# CM41x_M0 register map
Vendor: Analog Devices; Series: CM41x_M0; File version: 1p0
CPU: CM0 r0p0, little endian, MPU, FPU, 4 interrupt priority bits
Registers are 32-bit, read-write, reset 0x0 unless marked. A register's access mark holds for its fields unless they carry their own. Offsets are from the block's base; [hi:lo] are bit positions; {n}, {i} and the like mark numbered series.

## SYSBLK0 — Pads Controller
Base 0x41000000
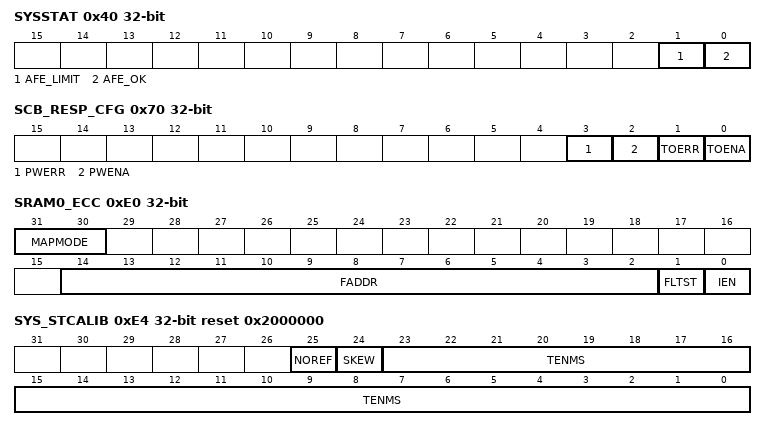
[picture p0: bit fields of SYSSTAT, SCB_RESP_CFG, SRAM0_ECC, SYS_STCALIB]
0x40 SYSSTAT — System Status Register
  [1] AFE_LIMIT ro — Status of AFE_LIMIT signal
  [0] AFE_OK ro — Status of AFE_OK Signal
0x70 SCB_RESP_CFG — SCB Response Configuration Register
  [3] PWERR — Posted Write Error
  [2] PWENA — Posted Write Error Interrupt Enable
  [1] TOERR — Timeout Error
  [0] TOENA — Enable SCB Timeout Interrupt
0x74 SCB_TIMEOUT_VALUE
  [15:0] DATA range 0x00000000..0x0000FFFF — Timeout Value
0x80 ENG_MODE_CFG0 — Engineering Mode Configuration Register 0
  [17] LBA_COMB_MODE range 0x00000000..0x00000001 — LBA Combinatorial mode
0xB4 M0_VTOR reset 0x200F0000 — Vector Table Base Offset Register
  [31:8] TBLOFF range 0x00000000..0x00FFFFFF — Vector Table Base Offset
0xE0 SRAM0_ECC — M0 SRAM ECC Register
  [31:30] MAPMODE range 0x00000000..0x00000003 — ECC Bypass Modes
  [14:2] FADDR ro — ECC Fault Address
  [1] FLTST range 0x00000000..0x00000001 — Fault Status
  [0] IEN range 0x00000000..0x00000001 — Interrupt Enable
0xE4 SYS_STCALIB reset 0x2000000 — System Register
  [25] NOREF ro — No External Reference
  [24] SKEW range 0x00000000..0x00000001 — SCLK exact multiple of 10ms
  [23:0] TENMS range 0x00000000..0x00FFFFFF — Tick Calibration 10s Microseconds
0xE8 IRQ_LATENCY reset 0xD — M0 IRQ Latency Register
  [7:0] VALUE range 0x00000000..0x000000FF — IRQ LATENCY VALUE
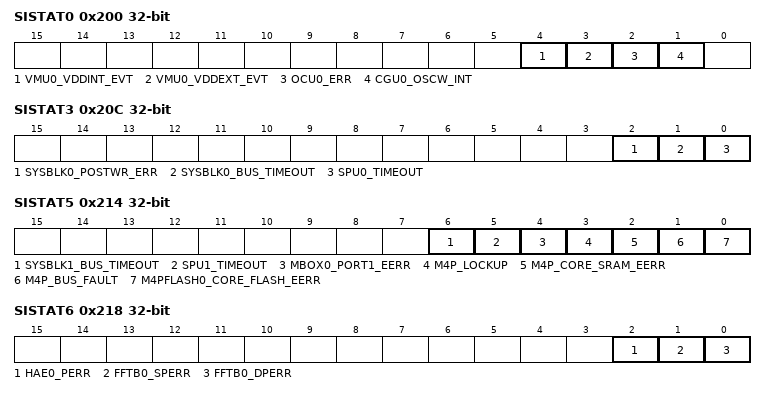
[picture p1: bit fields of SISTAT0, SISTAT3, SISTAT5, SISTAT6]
0x200 SISTAT0 — Shared Interrupt 0 Status Register
  [4] VMU0_VDDINT_EVT range 0x00000000..0x00000001 — Shared INTR_0 status bit (From VMU[0]_VDDINT_EVT)
  [3] VMU0_VDDEXT_EVT range 0x00000000..0x00000001 — Shared INTR_0 status bit (From VMU[0]_VDDEXT_EVT)
  [2] OCU0_ERR range 0x00000000..0x00000001 — Shared INTR_0 status bit (From OCU[0]_ERR)
  [1] CGU0_OSCW_INT range 0x00000000..0x00000001 — Shared INTR_0 status bit (From CGU[0]_OSCW_INT)
0x20C SISTAT3 — Shared Interrupt 3 Status Register
  [2] SYSBLK0_POSTWR_ERR range 0x00000000..0x00000001 — Shared INTR_3 status bit (From SYSBLK[0]_POSTWR_ERR)
  [1] SYSBLK0_BUS_TIMEOUT range 0x00000000..0x00000001 — Shared INTR_3 status bit (From SYSBLK[0]_BUS_TIMEOUT)
  [0] SPU0_TIMEOUT range 0x00000000..0x00000001 — Shared INTR_3 status bit (From SPU[0]_TIMEOUT)
0x214 SISTAT5 — Shared Interrupt 5 Status Register
  [6] SYSBLK1_BUS_TIMEOUT range 0x00000000..0x00000001 — Shared INTR_5 status bit (From SYSBLK[1]_BUS_TIMEOUT)
  [5] SPU1_TIMEOUT range 0x00000000..0x00000001 — Shared INTR_5 status bit (From SPU[1]_TIMEOUT)
  [4] MBOX0_PORT1_EERR range 0x00000000..0x00000001 — Shared INTR_5 status bit (From MBOX[0]_PORT1_EERR)
  [3] M4P_LOCKUP range 0x00000000..0x00000001 — Shared INTR_5 status bit (From M4P_LOCKUP)
  [2] M4P_CORE_SRAM_EERR range 0x00000000..0x00000001 — Shared INTR_5 status bit (From M4P_CORE_SRAM_EERR)
  [1] M4P_BUS_FAULT range 0x00000000..0x00000001 — Shared INTR_5 status bit (From M4P_BUS_FAULT)
  [0] M4PFLASH0_CORE_FLASH_EERR range 0x00000000..0x00000001 — Shared INTR_5 status bit (From M4PFLASH[0]_CORE_FLASH_EERR)
0x218 SISTAT6 — Shared Interrupt 6 Status Register
  [2] HAE0_PERR range 0x00000000..0x00000001 — Shared INTR_6 status bit (From HAE[0]_PERR)
  [1] FFTB0_SPERR range 0x00000000..0x00000001 — Shared INTR_6 status bit (From FFTB[0]_SPERR)
  [0] FFTB0_DPERR range 0x00000000..0x00000001 — Shared INTR_6 status bit (From FFTB[0]_DPERR)
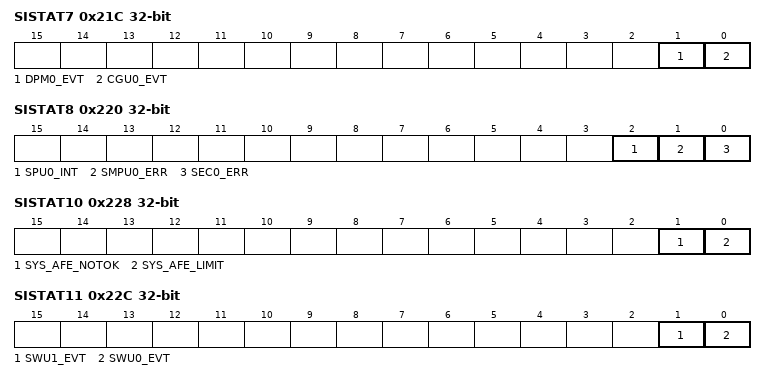
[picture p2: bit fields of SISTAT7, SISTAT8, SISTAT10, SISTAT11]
0x21C SISTAT7 — Shared Interrupt 7 Status Register
  [1] DPM0_EVT range 0x00000000..0x00000001 — Shared INTR_7 status bit (From DPM[0]_EVT)
  [0] CGU0_EVT range 0x00000000..0x00000001 — Shared INTR_7 status bit (From CGU[0]_EVT)
0x220 SISTAT8 — Shared Interrupt 8 Status Register
  [2] SPU0_INT range 0x00000000..0x00000001 — Shared INTR_8 status bit (From SPU[0]_INT)
  [1] SMPU0_ERR range 0x00000000..0x00000001 — Shared INTR_8 status bit (From SMPU[0]_ERR)
  [0] SEC0_ERR range 0x00000000..0x00000001 — Shared INTR_8 status bit (From SEC[0]_ERR)
0x228 SISTAT10 — Shared Interrupt 10 Status Register
  [1] SYS_AFE_NOTOK ro — Shared INTR_10 status bit (From SYS_AFE_NOTOK)
  [0] SYS_AFE_LIMIT range 0x00000000..0x00000001 — Shared INTR_10 status bit (From SYS_AFE_LIMIT)
0x22C SISTAT11 — Shared Interrupt 11 Status Register
  [1] SWU1_EVT range 0x00000000..0x00000001 — Shared INTR_11 status bit (From SWU[1]_EVT)
  [0] SWU0_EVT range 0x00000000..0x00000001 — Shared INTR_11 status bit (From SWU[0]_EVT)
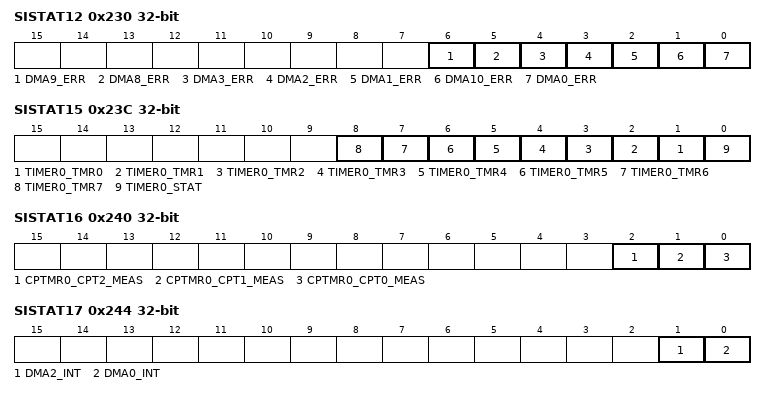
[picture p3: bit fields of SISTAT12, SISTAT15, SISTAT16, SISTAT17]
0x230 SISTAT12 — Shared Interrupt 12 Status Register
  [6] DMA9_ERR range 0x00000000..0x00000001 — Shared INTR_12 status bit (From DMA[9]_ERR)
  [5] DMA8_ERR range 0x00000000..0x00000001 — Shared INTR_12 status bit (From DMA[8]_ERR)
  [4] DMA3_ERR range 0x00000000..0x00000001 — Shared INTR_12 status bit (From DMA[3]_ERR)
  [3] DMA2_ERR range 0x00000000..0x00000001 — Shared INTR_12 status bit (From DMA[2]_ERR)
  [2] DMA1_ERR range 0x00000000..0x00000001 — Shared INTR_12 status bit (From DMA[1]_ERR)
  [1] DMA10_ERR range 0x00000000..0x00000001 — Shared INTR_12 status bit (From DMA[10]_ERR)
  [0] DMA0_ERR range 0x00000000..0x00000001 — Shared INTR_12 status bit (From DMA[0]_ERR)
0x23C SISTAT15 — Shared Interrupt 15 Status Register
  [n+1] TIMER0_TMR{n} range 0x00000000..0x00000001 (n=0..7) — Shared INTR_15 status bit (From TIMER[0]_TMR[{n}])
  [0] TIMER0_STAT range 0x00000000..0x00000001 — Shared INTR_15 status bit (From TIMER[0]_STAT)
0x240 SISTAT16 — Shared Interrupt 16 Status Register
  [2] CPTMR0_CPT2_MEAS range 0x00000000..0x00000001 — Shared INTR_16 status bit (From CPTMR[0]_CPT[2]_MEAS)
  [1] CPTMR0_CPT1_MEAS range 0x00000000..0x00000001 — Shared INTR_16 status bit (From CPTMR[0]_CPT[1]_MEAS)
  [0] CPTMR0_CPT0_MEAS range 0x00000000..0x00000001 — Shared INTR_16 status bit (From CPTMR[0]_CPT[0]_MEAS)
0x244 SISTAT17 — Shared Interrupt 17 Status Register
  [1] DMA2_INT range 0x00000000..0x00000001 — Shared INTR_17 status bit (From DMA[2]_INT)
  [0] DMA0_INT range 0x00000000..0x00000001 — Shared INTR_17 status bit (From DMA[0]_INT)
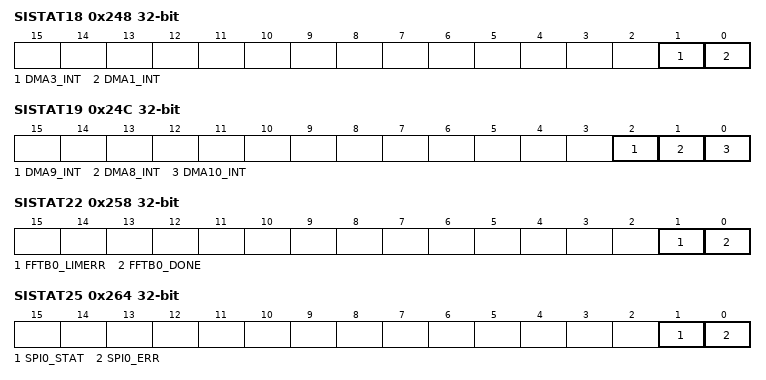
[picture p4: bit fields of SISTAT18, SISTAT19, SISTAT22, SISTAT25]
0x248 SISTAT18 — Shared Interrupt 18 Status Register
  [1] DMA3_INT range 0x00000000..0x00000001 — Shared INTR_18 status bit (From DMA[3]_INT)
  [0] DMA1_INT range 0x00000000..0x00000001 — Shared INTR_18 status bit (From DMA[1]_INT)
0x24C SISTAT19 — Shared Interrupt 19 Status Register
  [2] DMA9_INT range 0x00000000..0x00000001 — Shared INTR_19 status bit (From DMA[9]_INT)
  [1] DMA8_INT range 0x00000000..0x00000001 — Shared INTR_19 status bit (From DMA[8]_INT)
  [0] DMA10_INT range 0x00000000..0x00000001 — Shared INTR_19 status bit (From DMA[10]_INT)
0x258 SISTAT22 — Shared Interrupt 22 Status Register
  [1] FFTB0_LIMERR range 0x00000000..0x00000001 — Shared INTR_22 status bit (From FFTB[0]_LIMERR)
  [0] FFTB0_DONE range 0x00000000..0x00000001 — Shared INTR_22 status bit (From FFTB[0]_DONE)
0x264 SISTAT25 — Shared Interrupt 25 Status Register
  [1] SPI0_STAT range 0x00000000..0x00000001 — Shared INTR_25 status bit (From SPI[0]_STAT)
  [0] SPI0_ERR range 0x00000000..0x00000001 — Shared INTR_25 status bit (From SPI[0]_ERR)
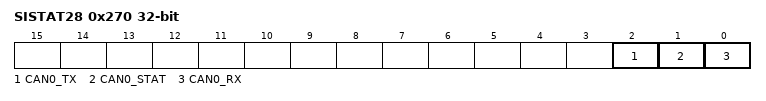
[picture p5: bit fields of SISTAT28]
0x270 SISTAT28 — Shared Interrupt 28 Status Register
  [2] CAN0_TX range 0x00000000..0x00000001 — Shared INTR_28 status bit (From CAN[0]_TX)
  [1] CAN0_STAT range 0x00000000..0x00000001 — Shared INTR_28 status bit (From CAN[0]_STAT)
  [0] CAN0_RX range 0x00000000..0x00000001 — Shared INTR_28 status bit (From CAN[0]_RX)
